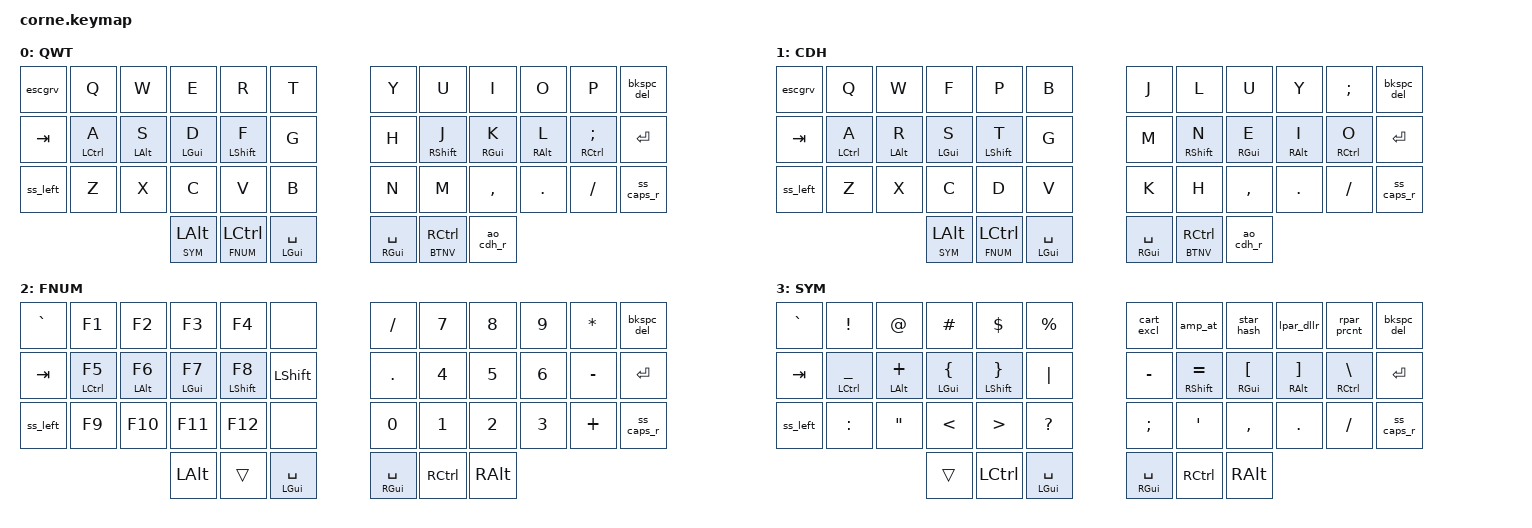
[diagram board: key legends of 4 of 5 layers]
/*
 * Copyright (c) 2020 The ZMK Contributors
 *
 * SPDX-License-Identifier: MIT
 */

// INCLUDES - START  ***********************************************************
// ZMK Core Includes
#include <behaviors.dtsi>
#include <dt-bindings/zmk/keys.h>
#include <dt-bindings/zmk/bt.h>
#include <dt-bindings/zmk/outputs.h>

// JINIUS Includes
// Key position includes
#include "corne_42keys.h"
// INCLUDES - ENDS *************************************************************

// DEFINES - START *************************************************************
// DEFINES LAYERS - START ******************************************************
// Layer shotcuts defined for easier identification.
// The order must match in which they are defined below.
#define QWT 0
#define CDH 1
#define FNUM 2
#define SYM 3
#define BTNV 4
// DEFINES LAYERS - ENDS *******************************************************
// DEFINES BLUETOOTH PROFILE SELECTION - START *********************************
#define BTP0 BT_SEL 0
#define BTP1 BT_SEL 1 
#define BTP2 BT_SEL 2
#define BTP3 BT_SEL 3
#define BTP4 BT_SEL 4
// DEFINES BLUETOOTH PROFILE SELECTION - ENDS **********************************

// DEFINES KEY TYPE ALIAS - START **********************************************
#define XXX &none   // To trap the key event in a given layer
#define ___ &trans  // To pass the key event to the next active layer
// DEFINES KEY TYPE ALIAS - ENDS ***********************************************

// DEFINES GLOBAL SETTINGS - START *********************************************
#define TAPPING_TERM_MS 280
#define QUICK_TAP_MS 175
#define REQUIRE_PRIOR_IDLE_MS 125
// DEFINES GLOBAL SETTINGS - ENDS **********************************************

// DEFINES KEY CONFIGURATION SETTINGS - START **********************************
&sk {  // sticky-key config
    release-after-ms = <900>;  // release after 0.6s
    quick-release;             // no double capitalization when rolling keys
};

&sl {  // sticky-layer config
    ignore-modifiers;          // allow chording sticky mods & layers
};

&lt {  // layer-tap config
    flavor = "balanced";
    tapping-term-ms = <200>;
    quick-tap-ms = <QUICK_TAP_MS>;
};
// DEFINES KEY CONFIGURATION SETTINGS - ENDS ***********************************

// DEFINES COMBINATION KEYS FOR HOMEROW MODS - START ***************************
#define LEFT_HAND_KEYS LT0 LT1 LT2 LT3 LT4 LT5 LM0 LM1 LM2 LM3 LM4 LM5 LB0 LB1 LB2 LB3 LB4 LB5
#define RIGHT_HAND_KEYS RT0 RT1 RT2 RT3 RT4 RT5 RM0 RM1 RM2 RM3 RM4 RM5 RB0 RB1 RB2 RB3 RB4 RB5
#define THUMB_KEYS LH0 LH1 LH2 RH0 RH1 RH2
// DEFINES COMBINATION KEYS FOR HOMEROW MODS - ENDS ****************************


// DEFINES - ENDS **************************************************************

// ROOT DEVICETREE NODE - START ************************************************
/ {

// BEHAVIOR - START ************************************************************
  // BEHAVIOR DEFINITIONS - START **********************************************
  // Homerow mod definition for left hand keys
  behaviors {
    /***********************************************
     **  Homerow mod for left split keyboard
     **  as explained here: https://github.com/urob/zmk-config#timeless-homerow-mods
     **  This is a expanded version of the same functionality along with the timings
     ***********************************************/
    hml: homerow_mod_left {
      label = "HOMEROW_MOD_LEFT";
      compatible = "zmk,behavior-hold-tap";
      #binding-cells = <2>;
      bindings = <&kp>, <&kp>;
      flavor = "balanced";
      tapping-term-ms = <TAPPING_TERM_MS>;
      quick-tap-ms = <QUICK_TAP_MS>;
      require-prior-idle-ms = <REQUIRE_PRIOR_IDLE_MS>;
      hold-trigger-key-positions = <RIGHT_HAND_KEYS THUMB_KEYS>;
    };
    /***********************************************
     **  Homerow mod for right split keyboard
     **  as explained here: https://github.com/urob/zmk-config#timeless-homerow-mods
     **  This is a expanded version of the same functionality along with the timings
     ***********************************************/
    hmr: homerow_mod_right {
      label = "HOMEROW_MOD_RIGHT";
      compatible = "zmk,behavior-hold-tap";
      #binding-cells = <2>;
      bindings = <&kp>, <&kp>;
      flavor = "balanced";
      tapping-term-ms = <TAPPING_TERM_MS>;
      quick-tap-ms = <QUICK_TAP_MS>;
      require-prior-idle-ms = <REQUIRE_PRIOR_IDLE_MS>;
      hold-trigger-key-positions = <LEFT_HAND_KEYS THUMB_KEYS>;
    };
    /***********************************************
     ** Momentary Sticky Mod: Momentary layer on hold and tap to sticky modifier
     ** Holding the key will switch to the layer, taping will configure the sticky modifier
     **   hold: momentary layer
     **   tap: sticky modifier
     ***********************************************/
    mosm: momentary_sticky_mod {
      label = "MOMENTARY_STICKY_MOD";
      compatible = "zmk,behavior-hold-tap";
      #binding-cells = <2>;
      bindings = <&mo>, <&sk>;
      flavor = "balanced";
      tapping-term-ms = <TAPPING_TERM_MS>;
      quick-tap-ms = <QUICK_TAP_MS>;
      require-prior-idle-ms = <REQUIRE_PRIOR_IDLE_MS>;
      hold-trigger-on-release;
    };
    /***********************************************
     ** Thumb Mod Tap: Hold to modifier, Tap to key press
     ** Holding the key will activate the modifier and tapping activates key press
     **   hold: Modifier
     **   tap: key-press
     ***********************************************/
    tmt: thumb_mod_tap {
      label = "THUMB_MOD_TAP";
      compatible = "zmk,behavior-hold-tap";
      #binding-cells = <2>;
      bindings = <&kp>, <&kp>;
      flavor = "balanced";
      tapping-term-ms = <TAPPING_TERM_MS>;
      quick-tap-ms = <QUICK_TAP_MS>;
      require-prior-idle-ms = <REQUIRE_PRIOR_IDLE_MS>;
      hold-trigger-on-release;
    };
    /***********************************************
     **  Smart Shift Key: As explained here: https://github.com/minusfive/zmk-config#smart-shift
     **  This configuration is for the left split keyboard
     **  Similar setup is defined for the right split keyboard
     **     hold: shift
     **     tap: sticky shift
     **     double-tap: caps-word
     ***********************************************/
    ss_left: smart_shift_left {
      label = "SMART_SHIFT_LEFT";
      compatible = "zmk,behavior-mod-morph";
      #binding-cells = <0>;
      bindings = <&sk LSHFT>, <&caps_word>;
      mods = <(MOD_LSFT)>;
    };
    /***********************************************
     **  CONTROL LAYER COLEMAKDH: On the right key board
     **     hold: shift
     **     tap: sticky key control
     **     double tap: caps-word
     **     triple tap: caps lock
     ***********************************************/
    ss_caps_r: smart_shift_capslock_right {
      label = "SMART_SHIFT_CAPSLOCK_RIGHT";
      compatible = "zmk,behavior-tap-dance";
      #binding-cells = <0>;
      tapping-term-ms = <200>;
      bindings = <&sk RSHFT>, <&caps_word>, <&kp CAPSLOCK>;
    };
    /***********************************************
     **  Backspace Delete: As defined here: https://github.com/minusfive/zmk-config/blob/main/knucklehead/behaviors.dtsi
     **     tap: backspace
     **     hold: repeat backspace
     **     shift + tap: delete
     **     shift + hold: repeat delete
     ***********************************************/
    bkspc_del: backspace_delete {
      label = "BACKSPACE_DELETE";
      compatible = "zmk,behavior-mod-morph";
      #binding-cells = <0>;
      bindings = <&kp BACKSPACE>, <&kp DELETE>;
      mods = <(MOD_LSFT|MOD_RSFT)>;
    };
    /***********************************************
     **  ESC Grave:
     **     tap: ESCAPE (ESC)
     **     hold: repeat ESCAPE (ESC)
     **     gui/command + tap: command + grave (~)
     **     gui/command + : repeat command + grave (~)
     ***********************************************/
    escgrv: escape_grave {
      compatible = "zmk,behavior-mod-morph";
      label = "ESCAPE_GRAVE";
      #binding-cells = <0>;
      bindings = <&kp ESC>, <&kp GRAVE>;
      mods = <(MOD_LGUI|MOD_RGUI)>;
      keep-mods = <(MOD_LGUI|MOD_RGUI)>;
    };
    /***********************************************
     **  Caret Exclamation:
     **     tap: caret (^)
     **     hold: repeat caret (^)
     **     shift + tap: exclamation (!)
     **     shift + hold: repeat exclamation (!)
     ***********************************************/
    cart_excl: caret_exclamation {
      label = "CARET_EXCLAMATION";
      compatible = "zmk,behavior-mod-morph";
      #binding-cells = <0>;
      bindings = <&kp CARET>, <&kp EXCL>;
      mods = <(MOD_LSFT|MOD_RSFT)>;
    };
    /***********************************************
     **  At Ampersand:
     **     tap: ampersand (&)
     **     hold: repeat ampersand (&)
     **     shift + tap: at (@)
     **     shift + hold: repeat at (@)
     ***********************************************/
    amp_at: ampersand_at {
      label = "AMPERSAND_AT";
      compatible = "zmk,behavior-mod-morph";
      #binding-cells = <0>;
      bindings = <&kp AMPS>, <&kp AT>;
      mods = <(MOD_LSFT|MOD_RSFT)>;
    };
    /***********************************************
     **  Star Hash:
     **     tap: star (*)
     **     hold: repeat star (*)
     **     shift + tap: hash (#)
     **     shift + hold: repeat hash (#)
     ***********************************************/
    star_hash: star_hash {
      label = "STAR_HASH";
      compatible = "zmk,behavior-mod-morph";
      #binding-cells = <0>;
      bindings = <&kp STAR>, <&kp HASH>;
      mods = <(MOD_LSFT|MOD_RSFT)>;
    };
    /***********************************************
     **  Left Parenthesis Dollar:
     **     tap: left parenthesis (()
     **     hold: repeat left parenthesis (()
     **     shift + tap: dollar ($)
     **     shift + hold: repeat dollar ($)
     ***********************************************/
    lpar_dllr: l_parenthesis_dollar {
      label = "LEFT_PARENTHESIS_DOLLAR";
      compatible = "zmk,behavior-mod-morph";
      #binding-cells = <0>;
      bindings = <&kp LPAR>, <&kp DOLLAR>;
      mods = <(MOD_LSFT|MOD_RSFT)>;
    };
    /***********************************************
     **  Right Parenthesis Percent:
     **     tap: right parenthesis ())
     **     hold: repeat right parenthesis ())
     **     shift + tap: percent (%)
     **     shift + hold: repeat percent (%)
     ***********************************************/
    rpar_prcnt: r_parenthesis_percent {
      label = "RIGHT_PARENTHESIS_PERCENT";
      compatible = "zmk,behavior-mod-morph";
      #binding-cells = <0>;
      bindings = <&kp RPAR>, <&kp PERCENT>;
      mods = <(MOD_LSFT|MOD_RSFT)>;
    };
    /***********************************************
     **  ALT/OPT LAYER COLEMAKDH: On the right key board
     **     tap: sticky key alt/opt
     **     hold: alt/opt
     **     double tap: toggle layer to Colemak-mDH
     ***********************************************/
    ao_cdh_r: alt_opt_cdh_right {
      label = "ALT_OPT_COLEMAKDH_RIGHT";
      compatible = "zmk,behavior-mod-morph";
      #binding-cells = <0>;
      bindings = <&sk RALT>, <&tog CDH>;
      mods = <(MOD_RALT)>;
    };
  };
  // BEHAVIOR DEFINITIONS - END ************************************************
// BEHAVIOR - ENDS *************************************************************

// KEYMAP NODE - START *********************************************************
  keymap {
    compatible = "zmk,keymap";
    // LAYERS - START **********************************************************
    // QWERTY layer
    qwerty_bt_layer {
      label = "QWT";
      bindings = <
// ╭────-──────────┬───────────────┬───────────────┬───────────────┬───────────────┬───────────────╮   ╭───────────────┬───────────────┬───────────────┬───────────────┬───────────────┬───────────────╮
// ├─   0 <LT5>   ─┼─   1 <LT4>   ─┼─   2 <LT3>   ─┼─   3 <LT2>   ─┼─   4 <LT1>   ─┼─   5 <LT0>   ─┤   ├─   6 <RT0>   ─┼─   7 <RT1>   ─┼─   8 <RT2>   ─┼─   9 <RT3>   ─┼─  10 <RT4>   ─┼─  11 <RT5>   ─┤
// ├─   ESC / ~   ─┼─      Q      ─┼─      W      ─┼─      E      ─┼─      R      ─┼─      T      ─┤   ├─      Y      ─┼─      U      ─┼─      I      ─┼─      O      ─┼─      P      ─┼─ <BKSPC/DEL> ─┤
        &escgrv           &kp Q           &kp W           &kp E           &kp R           &kp T              &kp Y            &kp U           &kp I           &kp O           &kp P        &bkspc_del
// ├─────-─────────├───────────────┼───────────────┼───────────────┼───────────────┼───────────────┤   ├───────────────├───────────────┼───────────────┼───────────────┼───────────────┼───────────────┤
// ├─  12 <LM5>   ─┼─  13 <LM4>   ─┼─  14 <LM3>   ─┼─  15 <LM2>   ─┼─  16 <LM1>   ─┼─  17 <LM0>   ─┤   ├─  18 <RM0>   ─┼─  19 <RM1>   ─┼─  20 <RM2>   ─┼─  21 <RM3>   ─┼─  22 <RM4>   ─┼─  23 <RM5>   ─┤
// ├─     TAB     ─┼─  LCTRL / A  ─┼─  LALT / S   ─┼─  LGUI / D   ─┼─  LSHFT / F  ─┼─      G      ─┤   ├─      H      ─┼─  RSHFT / J  ─┼─  RGUI / K   ─┼─  RALT / L   ─┼─  RCTRL / ;  ─┼─    RETURN   ─┤
        &kp TAB      &hml LCTRL A     &hml LALT S     &hml LGUI D     &hml LSHFT F       &kp G               &kp H        &hmr RSHFT J    &hmr RGUI K     &hmr RALT L   &hmr RCTRL SEMI      &kp RET
// ├───────────────├───────────────┼───────────────┼───────────────┼───────────────┼───────────────┤   ├───────────────├───────────────┼───────────────┼───────────────┼───────────────┼───────────────┤
// ├─  24 <LB5>   ─┼─  25 <LB4>   ─┼─  26 <LB3>   ─┼─  27 <LB2>   ─┼─  28 <LB1>   ─┼─  29 <LB0>   ─┤   ├─  30 <RB0>   ─┼─  31 <RB1>   ─┼─  32 <RB2>   ─┼─  33 <RB3>   ─┼─  34 <RB4>   ─┼─  35 <RB5>   ─┤
// ├─ SMART SHIFT ─┼─      Z      ─┼─      X      ─┼─      C      ─┼─      V      ─┼─      B      ─┤   ├─      N      ─┼─      M      ─┼─      ,      ─┼─      .      ─┼─      /      ─┼─ SMART SHIFT ─┤
       &ss_left          &kp Z           &kp X           &kp C           &kp V           &kp B               &kp N           &kp M         &kp COMMA        &kp DOT        &kp FSLH        &ss_caps_r
// ╰───────────────┴───────────────┴───────────────┼───────────────┼───────────────┼───────────────┤   ├───────────────├───────────────┼───────────────┼───────────────┴───────────────┴───────────────╯
//                                                 ├─  36 <LH2>   ─┼─  37 <LH1>   ─┼─  38 <LH0>   ─┤   ├─  39 <RH0>   ─┼─  40 <RH1>   ─┼─  41 <RH2>   ─┤
//                                                 ├─ ALT/OPT/SYM ─┼─  CTRL/FNUM  ─┼─   SPC/CMD   ─┤   ├─   SPC/CMD   ─┼─  CTRL/BTNV  ─┼─ ALT/OPT/CDH ─┤
                                                    &mosm SYM LALT &mosm FNUM LCTRL &tmt LGUI SPACE     &tmt RGUI SPACE &mosm BTNV RCTRL   &ao_cdh_r
//                                                 ╰───────────────┴───────────────┴───────────────╯   ╰───────────────┴───────────────┴───────────────╯
      >;
    };

    // Colemak Mod-DH: Primary layer. To learn and and use
    colemakdh_bt_layer {
      label = "CDH";
      bindings = <
// ╭───────────────┬───────────────┬───────────────┬───────────────┬───────────────┬───────────────╮   ╭───────────────┬───────────────┬───────────────┬───────────────┬───────────────┬───────────────╮
// ├─   0 <LT5>   ─┼─   1 <LT4>   ─┼─   2 <LT3>   ─┼─   3 <LT2>   ─┼─   4 <LT1>   ─┼─   5 <LT0>   ─┤   ├─   6 <RT0>   ─┼─   7 <RT1>   ─┼─   8 <RT2>   ─┼─   9 <RT3>   ─┼─  10 <RT4>   ─┼─  11 <RT5>   ─┤
// ├─   ESC / ~   ─┼─      Q      ─┼─      W      ─┼─      F      ─┼─      P      ─┼─      B      ─┤   ├─      J      ─┼─      L      ─┼─      U      ─┼─      Y      ─┼─      ;      ─┼─ <BKSPC/DEL> ─┤
        &escgrv          &kp Q           &kp W           &kp F           &kp P           &kp B              &kp J            &kp L           &kp U           &kp Y         &kp SEMI       &bkspc_del
// ├───────────────├───────────────┼───────────────┼───────────────┼───────────────┼───────────────┤   ├───────────────├───────────────┼───────────────┼───────────────┼───────────────┼───────────────┤
// ├─  12 <LM5>   ─┼─  13 <LM4>   ─┼─  14 <LM3>   ─┼─  15 <LM2>   ─┼─  16 <LM1>   ─┼─  17 <LM0>   ─┤   ├─  18 <RM0>   ─┼─  19 <RM1>   ─┼─  20 <RM2>   ─┼─  21 <RM3>   ─┼─  22 <RM4>   ─┼─  23 <RM5>   ─┤
// ├─     TAB     ─┼─  LCTRL / A  ─┼─  LALT / R   ─┼─  LGUI / S   ─┼─  LSHFT / T  ─┼─      G      ─┤   ├─      M      ─┼─  RSHFT / N  ─┼─  RGUI / E   ─┼─  RALT / I   ─┼─  RCTRL / O  ─┼─    RETURN   ─┤
        &kp TAB      &hml LCTRL A     &hml LALT R     &hml LGUI S     &hml LSHFT T       &kp G               &kp M        &hmr RSHFT N    &hmr RGUI E     &hmr RALT I     &hmr RCTRL O      &kp RET
// ├───────────────├───────────────┼───────────────┼───────────────┼───────────────┼───────────────┤   ├───────────────├───────────────┼───────────────┼───────────────┼───────────────┼───────────────┤
// ├─  24 <LB5>   ─┼─  25 <LB4>   ─┼─  26 <LB3>   ─┼─  27 <LB2>   ─┼─  28 <LB1>   ─┼─  29 <LB0>   ─┤   ├─  30 <RB0>   ─┼─  31 <RB1>   ─┼─  32 <RB2>   ─┼─  33 <RB3>   ─┼─  34 <RB4>   ─┼─  35 <RB5>   ─┤
// ├─ SMART SHIFT ─┼─      z      ─┼─      x      ─┼─      C      ─┼─      D      ─┼─      V      ─┤   ├─      K      ─┼─      H      ─┼─      ,      ─┼─      .      ─┼─      /      ─┼─ SMART SHIFT ─┤
       &ss_left         &kp Z           &kp X           &kp C           &kp D            &kp V               &kp K           &kp H         &kp COMMA        &kp DOT        &kp FSLH        &ss_caps_r
// ╰───────────────┴───────────────┴───────────────┼───────────────┼───────────────┼───────────────┤   ├───────────────├───────────────┼───────────────┼───────────────┴───────────────┴───────────────╯
//                                                 ├─  36 <LH2>   ─┼─  37 <LH1>   ─┼─  38 <LH0>   ─┤   ├─  39 <RH0>   ─┼─  40 <RH1>   ─┼─  41 <RH2>   ─┤
//                                                 ├─ ALT/OPT/SYM ─┼─  CTRL/FNUM  ─┼─   SPC/CMD   ─┤   ├─   SPC/CMD   ─┼─  CTRL/BTNV  ─┼─ ALT/OPT/CDH ─┤
                                                    &mosm SYM LALT &mosm FNUM LCTRL &tmt LGUI SPACE     &tmt RGUI SPACE &mosm BTNV RCTRL   &ao_cdh_r
//                                                 ╰───────────────┴───────────────┴───────────────╯   ╰───────────────┴───────────────┴───────────────╯
      >;
    };

    // Function and Number layer
    function_number_layer {
      label = "FNUM";
      bindings = <
// ╭───────────────┬───────────────┬───────────────┬───────────────┬───────────────┬───────────────╮   ╭───────────────┬───────────────┬───────────────┬───────────────┬───────────────┬───────────────╮
// ├─   0 <LT5>   ─┼─   1 <LT4>   ─┼─   2 <LT3>   ─┼─   3 <LT2>   ─┼─   4 <LT1>   ─┼─   5 <LT0>   ─┤   ├─   6 <RT0>   ─┼─   7 <RT1>   ─┼─   8 <RT2>   ─┼─   9 <RT3>   ─┼─  10 <RT4>   ─┼─  11 <RT5>   ─┤
// ├─    ` / ~    ─┼─      F1     ─┼─      F2     ─┼─      F3     ─┼─      F4     ─┼─     NONE    ─┤   ├─      /      ─┼─       7     ─┼─       8     ─┼─       9     ─┼─       *     ─┼─ <BKSPC/DEL> ─┤
       &kp GRAVE        &kp F1          &kp F2          &kp F3          &kp F4            XXX             &kp FSLH         &kp N7          &kp N8          &kp N9          &kp STAR        &bkspc_del
// ├───────────────├───────────────┼───────────────┼───────────────┼───────────────┼───────────────┤   ├───────────────├───────────────┼───────────────┼───────────────┼───────────────┼───────────────┤
// ├─  12 <LM5>   ─┼─  13 <LM4>   ─┼─  14 <LM3>   ─┼─  15 <LM2>   ─┼─  16 <LM1>   ─┼─  17 <LM0>   ─┤   ├─  18 <RM0>   ─┼─  19 <RM1>   ─┼─  20 <RM2>   ─┼─  21 <RM3>   ─┼─  22 <RM4>   ─┼─  23 <RM5>   ─┤
// ├─     TAB     ─┼─  LCTRL / F5 ─┼─  LALT / F6  ─┼─  LGUI / F7  ─┼─  LSHFT / F8 ─┼─    LSHFT    ─┤   ├─      .      ─┼─       4     ─┼─       5     ─┼─       6     ─┼─       -     ─┼─    RETURN   ─┤
        &kp TAB      &hml LCTRL F5    &hml LALT F6    &hml LGUI F7   &hml LSHFT F8     &kp LSHFT           &kp DOT          &kp N4          &kp N5          &kp N6         &kp MINUS         &kp RET
// ├───────────────├───────────────┼───────────────┼───────────────┼───────────────┼───────────────┤   ├───────────────├───────────────┼───────────────┼───────────────┼───────────────┼───────────────┤
// ├─  24 <LB5>   ─┼─  25 <LB4>   ─┼─  26 <LB3>   ─┼─  27 <LB2>   ─┼─  28 <LB1>   ─┼─  29 <LB0>   ─┤   ├─  30 <RB0>   ─┼─  31 <RB1>   ─┼─  32 <RB2>   ─┼─  33 <RB3>   ─┼─  34 <RB4>   ─┼─  35 <RB5>   ─┤
// ├─ SMART SHIFT ─┼─      F9     ─┼─     F10     ─┼─      F11    ─┼─      F12    ─┼─     NONE    ─┤   ├─      0      ─┼─      1      ─┼─      2      ─┼─      3      ─┼─      +      ─┼─ SMART SHIFT ─┤
       &ss_left         &kp F9          &kp F10         &kp F11          &kp F12          XXX               &kp N0          &kp N1          &kp N2          &kp N3          &kp PLUS       &ss_caps_r
// ╰───────────────┴───────────────┴───────────────┼───────────────┼───────────────┼───────────────┤   ├───────────────├───────────────┼───────────────┼───────────────┴───────────────┴───────────────╯
//                                                 ├─  36 <LH2>   ─┼─  37 <LH1>   ─┼─  38 <LH0>   ─┤   ├─  39 <RH0>   ─┼─  40 <RH1>   ─┼─  41 <RH2>   ─┤
//                                                 ├─   ALT/OPT   ─┼─    ___      ─┼─   SPC/CMD   ─┤   ├─   SPC/CMD   ─┼─  CTRL/BTNV  ─┼─   ALT/OPT   ─┤
                                                       &kp LALT          ___        &tmt LGUI SPACE     &tmt RGUI SPACE    &kp RCTRL       &kp RALT
//                                                 ╰───────────────┴───────────────┴───────────────╯   ╰───────────────┴───────────────┴───────────────╯
      >;
    };

    // Symbols layer
    symbols_layer {
      label = "SYM";
      bindings = <
// ╭───────────────┬───────────────┬───────────────┬───────────────┬───────────────┬───────────────╮   ╭───────────────┬───────────────┬───────────────┬───────────────┬───────────────┬───────────────╮
// ├─   0 <LT5>   ─┼─   1 <LT4>   ─┼─   2 <LT3>   ─┼─   3 <LT2>   ─┼─   4 <LT1>   ─┼─   5 <LT0>   ─┤   ├─   6 <RT0>   ─┼─   7 <RT1>   ─┼─   8 <RT2>   ─┼─   9 <RT3>   ─┼─  10 <RT4>   ─┼─  11 <RT5>   ─┤
// ├─    ` / ~    ─┼─      !      ─┼─      @      ─┼─      #      ─┼─      $      ─┼─      %      ─┤   ├─    ! / ^    ─┼─    @ / &    ─┼─    # / *    ─┼─    $ / (    ─┼─    % / )    ─┼─ <BKSPC/DEL> ─┤
       &kp GRAVE       &kp EXCL         &kp AT         &kp HASH        &kp DLLR        &kp PRCNT           &cart_excl       &amp_at        &star_hash      &lpar_dllr     &rpar_prcnt      &bkspc_del
// ├───────────────├───────────────┼───────────────┼───────────────┼───────────────┼───────────────┤   ├───────────────├───────────────┼───────────────┼───────────────┼───────────────┼───────────────┤
// ├─  12 <LM5>   ─┼─  13 <LM4>   ─┼─  14 <LM3>   ─┼─  15 <LM2>   ─┼─  16 <LM1>   ─┼─  17 <LM0>   ─┤   ├─  18 <RM0>   ─┼─  19 <RM1>   ─┼─  20 <RM2>   ─┼─  21 <RM3>   ─┼─  22 <RM4>   ─┼─  23 <RM5>   ─┤
// ├─     TAB     ─┼─  LCTRL / _  ─┼─  LALT / +   ─┼─  LGUI / {   ─┼─  LSHFT / }  ─┼─      |      ─┤   ├─    - / _    ─┼─RSHFT / = / +─┼─ RGUI / [ / {─┼─ RALT / ] / }─┼─RCTRL / \ / |─┼─    RETURN   ─┤
        &kp TAB     &hml LCTRL UNDER &hml LALT PLUS  &hml LGUI LBRC &hml LSHFT RBRC    &kp PIPE           &kp MINUS     &hmr RSHFT EQUAL &hmr RGUI LBKT  &hmr RALT RBKT &hmr RCTRL BSLH     &kp RET
// ├───────────────├───────────────┼───────────────┼───────────────┼───────────────┼───────────────┤   ├───────────────├───────────────┼───────────────┼───────────────┼───────────────┼───────────────┤
// ├─  24 <LB5>   ─┼─  25 <LB4>   ─┼─  26 <LB3>   ─┼─  27 <LB2>   ─┼─  28 <LB1>   ─┼─  29 <LB0>   ─┤   ├─  30 <RB0>   ─┼─  31 <RB1>   ─┼─  32 <RB2>   ─┼─  33 <RB3>   ─┼─  34 <RB4>   ─┼─  35 <RB5>   ─┤
// ├─ SMART SHIFT ─┼─      :      ─┼─      "      ─┼─      <      ─┼─      >      ─┼─      ?      ─┤   ├─    ; / :    ─┼─    ' / "    ─┼─    , / <    ─┼─    . / >    ─┼─   / / ?     ─┼─ SMART SHIFT ─┤
       &ss_left        &kp COLON        &kp DQT         &kp LT          &kp GT         &kp QMARK           &kp SEMI         &kp SQT        &kp COMMA        &kp DOT        &kp FSLH        &ss_caps_r
// ╰───────────────┴───────────────┴───────────────┼───────────────┼───────────────┼───────────────┤   ├───────────────├───────────────┼───────────────┼───────────────┴───────────────┴───────────────╯
//                                                 ├─  36 <LH2>   ─┼─  37 <LH1>   ─┼─  38 <LH0>   ─┤   ├─  39 <RH0>   ─┼─  40 <RH1>   ─┼─  41 <RH2>   ─┤
//                                                 ├─     ___     ─┼─     CTRL    ─┼─     CMD     ─┤   ├─ SPC/CMD/FN  ─┼─     CTRL    ─┼─   ALT/OPT   ─┤
                                                          ___          &kp LCTRL    &tmt LGUI SPACE     &tmt RGUI SPACE    &kp RCTRL       &kp RALT
//                                                 ╰───────────────┴───────────────┴───────────────╯   ╰───────────────┴───────────────┴───────────────╯
      >;
    };

    // Bluetooth and Navigation layer
    bt_navigation_layer {
      label = "BTNV";
      bindings = <
// ╭───────────────┬───────────────┬───────────────┬───────────────┬───────────────┬───────────────╮   ╭───────────────┬───────────────┬───────────────┬───────────────┬───────────────┬───────────────╮
// ├─   0 <LT5>   ─┼─   1 <LT4>   ─┼─   2 <LT3>   ─┼─   3 <LT2>   ─┼─   4 <LT1>   ─┼─   5 <LT0>   ─┤   ├─   6 <RT0>   ─┼─   7 <RT1>   ─┼─   8 <RT2>   ─┼─   9 <RT3>   ─┼─  10 <RT4>   ─┼─  11 <RT5>   ─┤
// ├─   ESC / ~   ─┼─   OUT USB   ─┼─  BOOTLOADER ─┼─    BT CLR   ─┼─    RESET    ─┼─   OUT BLE   ─┤   ├─     HOME    ─┼─     NONE    ─┼─      UP     ─┼─    NONE     ─┼─    PG UP    ─┼─ <BKSPC/DEL> ─┤
        &escgrv       &out OUT_USB    &bootloader      &bt BT_CLR      &sys_reset     &out OUT_BLE          &kp HOME          XXX           &kp UP           XXX           &kp PG_UP       &bkspc_del
// ├───────────────├───────────────┼───────────────┼───────────────┼───────────────┼───────────────┤   ├───────────────├───────────────┼───────────────┼───────────────┼───────────────┼───────────────┤
// ├─  12 <LM5>   ─┼─  13 <LM4>   ─┼─  14 <LM3>   ─┼─  15 <LM2>   ─┼─  16 <LM1>   ─┼─  17 <LM0>   ─┤   ├─  18 <RM0>   ─┼─  19 <RM1>   ─┼─  20 <RM2>   ─┼─  21 <RM3>   ─┼─  22 <RM4>   ─┼─  23 <RM5>   ─┤
// ├─     TAB     ─┼─ LCTRL / NONE─┼─ LALT / NONE ─┼─  LGUI / NONE─┼─ LSHFT / NONE─┼─     NONE    ─┤   ├─     END     ─┼─ RSHFT / LEFT─┼─ RGUI / DOWN ─┼─ RALT / RIGHT─┼─RCTRL / PG DN─┼─    RETURN   ─┤
        &kp TAB     &hml LCTRL XXX   &hml LALT XXX   &hml LGUI XXX   &hml LSHFT XXX       XXX               &kp END     &hmr RSHFT LEFT  &hmr RGUI DOWN &hmr RALT RIGHT &hmr RCTRL PG_DN     &kp RET
// ├───────────────├───────────────┼───────────────┼───────────────┼───────────────┼───────────────┤   ├───────────────├───────────────┼───────────────┼───────────────┼───────────────┼───────────────┤
// ├─  24 <LB5>   ─┼─  25 <LB4>   ─┼─  26 <LB3>   ─┼─  27 <LB2>   ─┼─  28 <LB1>   ─┼─  29 <LB0>   ─┤   ├─  30 <RB0>   ─┼─  31 <RB1>   ─┼─  32 <RB2>   ─┼─  33 <RB3>   ─┼─  34 <RB4>   ─┼─  35 <RB5>   ─┤
// ├─ SMART SHIFT ─┼─      BT0    ─┼─      BT1    ─┼─      BT2    ─┼─     BT3     ─┼─      BT4    ─┤   ├─     NONE    ─┼─     NONE    ─┼─  BRIGHT UP  ─┼─  BRIGHT DN  ─┼─    NONE     ─┼─ SMART SHIFT ─┤
       &ss_left       &bt BT_SEL 0    &bt BT_SEL 1    &bt BT_SEL 2    &bt BT_SEL 3    &bt BT_SEL 4            XXX             XXX         &kp C_BRI_UP    &kp C_BRI_DN       XXX          &ss_caps_r
// ╰───────────────┴───────────────┴───────────────┼───────────────┼───────────────┼───────────────┤   ├───────────────├───────────────┼───────────────┼───────────────┴───────────────┴───────────────╯
//                                                 ├─  36 <LH2>   ─┼─  37 <LH1>   ─┼─  38 <LH0>   ─┤   ├─  39 <RH0>   ─┼─  40 <RH1>   ─┼─  41 <RH2>   ─┤
//                                                 ├─   ALT/OPT   ─┼─     CTRL    ─┼─   SPC/CMD   ─┤   ├─   SPC/CMD   ─┼─     ___     ─┼─   ALT/OPT   ─┤
                                                       &kp LALT        &kp LCTRL    &tmt LGUI SPACE     &tmt RGUI SPACE       ___          &kp RALT    
//                                                 ╰───────────────┴───────────────┴───────────────╯   ╰───────────────┴───────────────┴───────────────╯
      >;
    };

// LAYERS - ENDS ***************************************************************
  };
// KEYMAP NODE - ENDS **********************************************************
};
// ROOT DEVICETREE NODE - ENDS *************************************************
